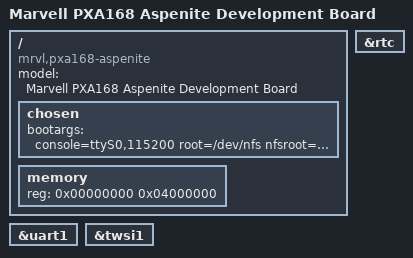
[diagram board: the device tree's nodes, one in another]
// SPDX-License-Identifier: GPL-2.0-only
/*
 *  Copyright (C) 2012 Marvell Technology Group Ltd.
 *  Author: Haojian Zhuang <haojian.zhuang@marvell.com>
 */

/dts-v1/;
#include "pxa168.dtsi"

/ {
	model = "Marvell PXA168 Aspenite Development Board";
	compatible = "mrvl,pxa168-aspenite", "mrvl,pxa168";

	chosen {
		bootargs = "console=ttyS0,115200 root=/dev/nfs nfsroot=192.168.1.100:/nfsroot/ ip=192.168.1.101:192.168.1.100::255.255.255.0::eth0:on";
	};

	memory {
		reg = <0x00000000 0x04000000>;
	};
};

&uart1 {
	status = "okay";
};

&twsi1 {
	status = "okay";
};

&rtc {
	status = "okay";
};
